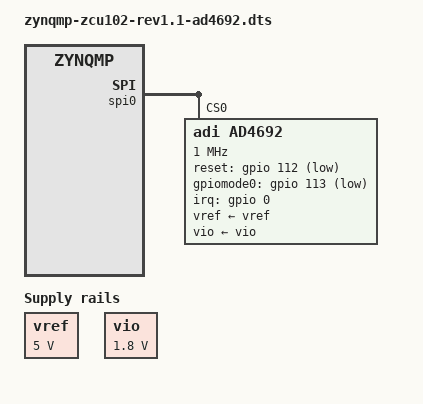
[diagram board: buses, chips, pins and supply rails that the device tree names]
// SPDX-License-Identifier: GPL-2.0
/*
 * Analog Devices AD4692
 *
 * Copyright (C) 2024 Analog Devices Inc.
 */

#include "zynqmp-zcu102-rev1.1.dts"
#include <dt-bindings/interrupt-controller/irq.h>
#include <dt-bindings/gpio/gpio.h>
#include <dt-bindings/pwm/pwm.h>

/ {

	vref: regulator-vref {
		compatible = "regulator-fixed";
		regulator-name = "fixed-supply";
		regulator-min-microvolt = <5000000>;
		regulator-max-microvolt = <5000000>;
		regulator-always-on;
	};

	vio: regulator-vio {
		compatible = "regulator-fixed";
		regulator-name = "fixed-supply";
		regulator-min-microvolt = <1800000>;
		regulator-max-microvolt = <1800000>;
		regulator-always-on;
	};
};

&spi0 {
	status = "okay";

	ad4692@0 {
		#address-cells = <1>;
		#size-cells = <0>;

		compatible = "adi,ad4692";
		reg = <0>;

		spi-max-frequency = <1000000>;
		vref-supply = <&vref>;
		vio-supply = <&vio>;

		reset-gpios = <&gpio 112 GPIO_ACTIVE_LOW>;
		gpiomode0-gpios = <&gpio 113 GPIO_ACTIVE_LOW>;

		//clocks = <&ref_clk>;
		//pwms = <&axi_pwm_gen 0 0>;
		//pwm-names = "cnv";

		interrupt-parent = <&gpio>;
		interrupts = <0 IRQ_TYPE_EDGE_FALLING>;
		interrupt-names = "data-ready";

		adi,spi-mode = <2>;
	};
};
